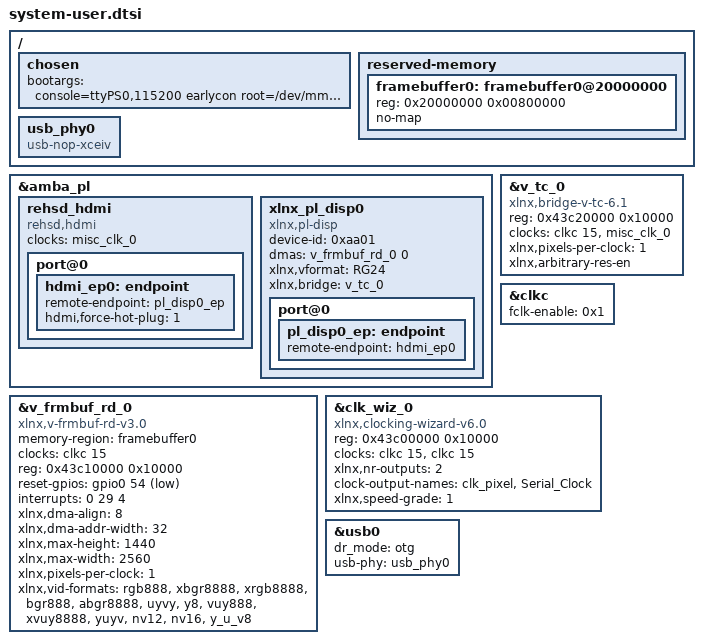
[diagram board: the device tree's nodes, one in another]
/include/ "system-conf.dtsi"

/ {
    chosen {
        bootargs = "console=ttyPS0,115200 earlycon root=/dev/mmcblk0p2 rw rootwait cma=256M video=HDMI-A-1:1280x720M-32@60 ";
    };

        reserved-memory {
			#address-cells = <1>;
			#size-cells = <1>;
			ranges;

			framebuffer0: framebuffer0@20000000 {
				reg = <0x20000000 0x00800000>; // 8 MB for framebuffer
				no-map;
			};
        };

    usb_phy0: usb_phy0 {
        compatible = "usb-nop-xceiv";
        #phy-cells = <0>;
    };
};

&amba_pl {
    /* HDMI Encoder node */
    rehsd_hdmi: rehsd_hdmi {
        compatible = "rehsd,hdmi", "xlnx,v-hdmi-tx-ss-1.0";
        clocks = <&misc_clk_0>;
        clock-names = "clk";
        status = "okay";

        // rehsd,edid-i2c = <&i2c0>;

		port@0 { 
            // reg = <0>;
			hdmi_ep0: endpoint { 
				remote-endpoint = <&pl_disp0_ep>; 
				hdmi,force-hot-plug = <1>;
			}; 
		}; 
    };

   	xlnx_pl_disp0 {
		compatible = "xlnx,pl-disp";
		device-id = <0xaa01>;
		dmas = <&v_frmbuf_rd_0 0>; 	
		dma-names = "dma0"; 
		xlnx,vformat = "RG24";		//Rg24
		xlnx,bridge = <&v_tc_0>; 
		status = "okay";

		port@0 { 
            // reg = <0>;
			pl_disp0_ep: endpoint { 
				remote-endpoint = <&hdmi_ep0>; 
			}; 
		};
	};
};

&v_frmbuf_rd_0 {
	// #dma-cells = <1>;
	memory-region = <&framebuffer0>;
	clock-names = "ap_clk";
	clocks = <&clkc 15>;
	compatible = "xlnx,v-frmbuf-rd-v3.0", "xlnx,axi-frmbuf-rd-v2.2";
	reg = <0x43c10000 0x10000>;      // Base address and size
    reset-gpios = <&gpio0 54 1>;
	// gpio-names = "reset";		//"reset"
	// interrupt-names = "interrupt";
	// interrupt-parent = <&intc>;
	interrupts = <0 29 4>;          // Interrupts configuration
	xlnx,dma-align = <8>;
	xlnx,dma-addr-width = <32>;     // Width of the DMA address
	xlnx,max-height = <1440>;        // Maximum vertical resolution
	xlnx,max-width = <2560>;        // Maximum horizontal resolution
	xlnx,pixels-per-clock = <1>;    // Pixels per clock cycle
	xlnx,vid-formats = "rgb888", "xbgr8888", "xrgb8888", "bgr888", "abgr8888", "uyvy", "y8", "vuy888", "xvuy8888", "yuyv", "nv12", "nv16", "y_u_v8";
	status = "okay";                // Enable the node
};

&v_tc_0 {
    compatible = "xlnx,bridge-v-tc-6.1";
    reg = <0x43c20000 0x10000>;
    clock-names = "s_axi_aclk", "clk";
    clocks = <&clkc 15>, <&misc_clk_0>;  // AXI 时钟和视频时钟
    xlnx,pixels-per-clock = <1>;  // 已存在，匹配 HDMI 720p
    xlnx,arbitrary-res-en;  // 可选，启用任意分辨率
    status = "okay";
};

&clkc {
    fclk-enable = <0x1>;
};

&clk_wiz_0 {
    compatible = "xlnx,clocking-wizard-v6.0", "xlnx,clocking-wizard";
    reg = <0x43c00000 0x10000>;
    #clock-cells = <1>;
    clocks = <&clkc 15>, <&clkc 15>;
    clock-names = "clk_in1", "s_axi_aclk";
    /* Outputs defined according to Vivado BD: clk_pixel = clk_out1, Serial_Clock = clk_out2 */
    xlnx,nr-outputs = <2>;
    clock-output-names = "clk_pixel", "Serial_Clock";
    //assigned-clocks = <&clk_wiz_0 0>, <&clk_wiz_0 1>;
    //assigned-clock-rates = <74250000>, <371250000>;    // out1=74.25MHz，out2=371.25MHz
    //clock-accuracy = <5000>; // 单位ppm（百万分比），覆盖驱动“零偏差”默认值
    xlnx,speed-grade = <1>;
    status = "okay";
};

&usb0 {
    dr_mode = "otg";
    usb-phy = <&usb_phy0>;
};
